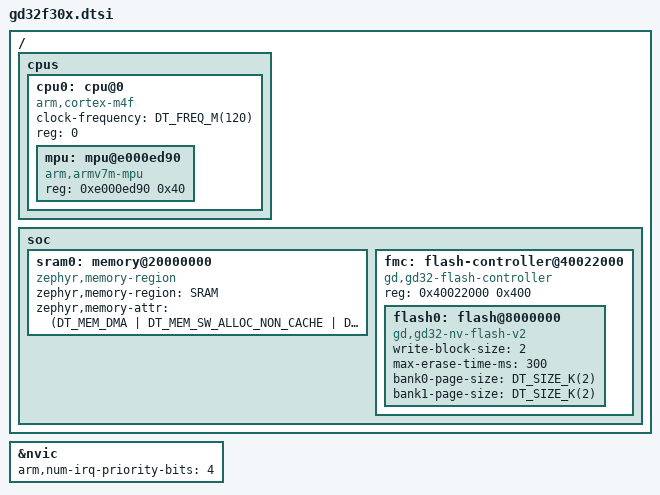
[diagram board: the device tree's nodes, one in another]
/*
 * Copyright (c) 2026 Zewen Zhu
 *
 * SPDX-License-Identifier: Apache-2.0
 */

#include <freq.h>
#include <arm/armv7-m.dtsi>
#include <zephyr/dt-bindings/memory-attr/memory-attr.h>
#include <zephyr/dt-bindings/memory-attr/memory-attr-sw.h>

/ {
	cpus {
		#address-cells = <1>;
		#size-cells = <0>;

		cpu0: cpu@0 {
			compatible = "arm,cortex-m4f";
			clock-frequency = <DT_FREQ_M(120)>;
			reg = <0>;
			#address-cells = <1>;
			#size-cells = <1>;

			mpu: mpu@e000ed90 {
				compatible = "arm,armv7m-mpu";
				reg = <0xe000ed90 0x40>;
			};
		};
	};

	soc {
		sram0: memory@20000000 {
			compatible = "zephyr,memory-region", "mmio-sram";
			zephyr,memory-region = "SRAM";
			zephyr,memory-attr = <(DT_MEM_DMA |
					       DT_MEM_SW_ALLOC_NON_CACHE |
					       DT_MEM_SW_ALLOC_DMA)>;
		};

		fmc: flash-controller@40022000 {
			compatible = "gd,gd32-flash-controller";
			reg = <0x40022000 0x400>;
			ranges;
			#address-cells = <1>;
			#size-cells = <1>;

			flash0: flash@8000000 {
				compatible = "gd,gd32-nv-flash-v2", "soc-nv-flash";
				write-block-size = <2>;
				max-erase-time-ms = <300>;
				bank0-page-size = <DT_SIZE_K(2)>;
				bank1-page-size = <DT_SIZE_K(2)>;
				#address-cells = <1>;
				#size-cells = <1>;
			};
		};
	};
};

&nvic {
	arm,num-irq-priority-bits = <4>;
};
